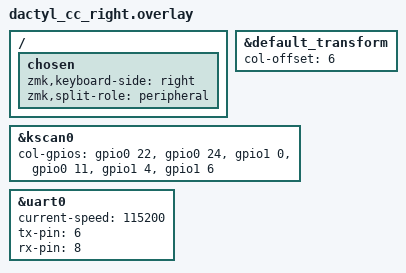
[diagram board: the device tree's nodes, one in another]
// dactyl_cc_right.overlay

#include "dactyl_cc.dtsi"

&default_transform { // The matrix transform for this board is 6 columns over because the left half is 6 columns wide according to the matrix.
    col-offset = <6>;
};

&kscan0 {
    col-gpios
        = <&gpio0 22 GPIO_ACTIVE_HIGH> // col5 in the schematic
        , <&gpio0 24 GPIO_ACTIVE_HIGH> // col4 in the schematic
        , <&gpio1 0  GPIO_ACTIVE_HIGH> // col3 in the schematic
        , <&gpio0 11 GPIO_ACTIVE_HIGH> // col2 in the schematic
        , <&gpio1 4  GPIO_ACTIVE_HIGH> // col1 in the schematic
        , <&gpio1 6  GPIO_ACTIVE_HIGH> // col0 in the schematic
        ;
};

/ {
    chosen {
        zmk,keyboard-side = "right";
        zmk,split-role = "peripheral"; // slave
    };
};

&uart0 {
    status = "okay";
    current-speed = <115200>;
    tx-pin = <6>;  // P0.06
    rx-pin = <8>;  // P0.08
};
